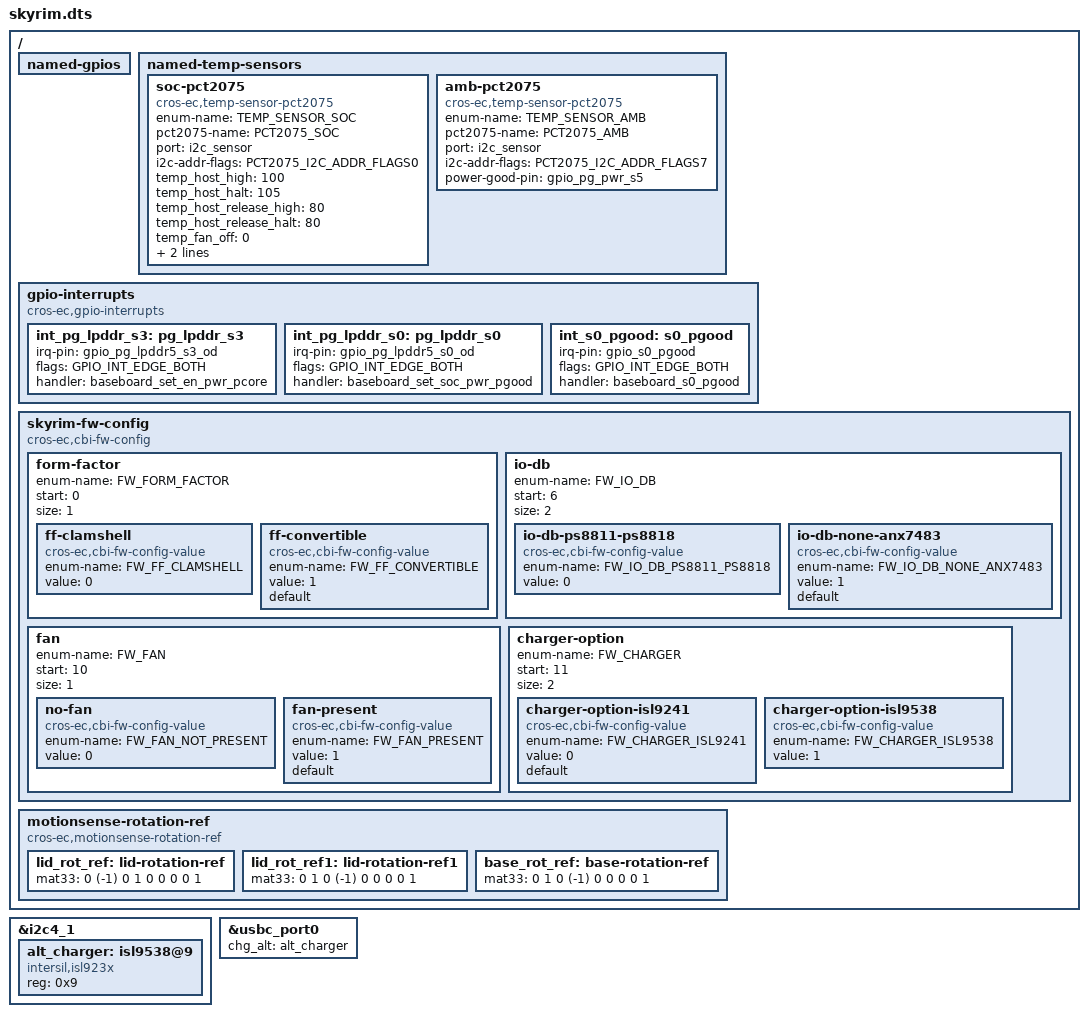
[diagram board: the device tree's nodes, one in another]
/* Copyright 2021 The Chromium OS Authors. All rights reserved.
 * Use of this source code is governed by a BSD-style license that can be
 * found in the LICENSE file.
 */

/ {
	named-gpios {
		/* Skyrim-specific GPIO customizations */
	};

	named-temp-sensors {
		soc-pct2075 {
			compatible = "cros-ec,temp-sensor-pct2075",
				     "cros-ec,temp-sensor";
			enum-name = "TEMP_SENSOR_SOC";
			pct2075-name = "PCT2075_SOC";
			port = <&i2c_sensor>;
			i2c-addr-flags = "PCT2075_I2C_ADDR_FLAGS0";
			temp_host_high = <100>;
			temp_host_halt = <105>;
			temp_host_release_high = <80>;
			temp_host_release_halt = <80>;
			temp_fan_off = <0>;
			temp_fan_max = <70>;
			power-good-pin = <&gpio_pg_pwr_s5>;
		};
		amb-pct2075 {
			compatible = "cros-ec,temp-sensor-pct2075",
				     "cros-ec,temp-sensor";
			enum-name = "TEMP_SENSOR_AMB";
			pct2075-name = "PCT2075_AMB";
			port = <&i2c_sensor>;
			i2c-addr-flags = "PCT2075_I2C_ADDR_FLAGS7";
			power-good-pin = <&gpio_pg_pwr_s5>;
		};
	};

	gpio-interrupts {
		compatible = "cros-ec,gpio-interrupts";

		int_pg_lpddr_s3: pg_lpddr_s3 {
			irq-pin = <&gpio_pg_lpddr5_s3_od>;
			flags = <GPIO_INT_EDGE_BOTH>;
			handler = "baseboard_set_en_pwr_pcore";
		};
		int_pg_lpddr_s0: pg_lpddr_s0 {
			irq-pin = <&gpio_pg_lpddr5_s0_od>;
			flags = <GPIO_INT_EDGE_BOTH>;
			handler = "baseboard_set_soc_pwr_pgood";
		};
		int_s0_pgood: s0_pgood {
			irq-pin = <&gpio_s0_pgood>;
			flags = <GPIO_INT_EDGE_BOTH>;
			handler = "baseboard_s0_pgood";
		};
	};

	/*
	 * Note this is expected to vary per-board, so we keep it in the board
	 * dts files.
	 */
	skyrim-fw-config {
		compatible = "cros-ec,cbi-fw-config";

		form-factor {
			enum-name = "FW_FORM_FACTOR";
			start = <0>;
			size = <1>;

			ff-clamshell {
				compatible = "cros-ec,cbi-fw-config-value";
				enum-name = "FW_FF_CLAMSHELL";
				value = <0>;
			};
			ff-convertible {
				compatible = "cros-ec,cbi-fw-config-value";
				enum-name = "FW_FF_CONVERTIBLE";
				value = <1>;
				default;
			};
		};
		io-db {
			enum-name = "FW_IO_DB";
			start = <6>;
			size = <2>;

			io-db-ps8811-ps8818 {
				compatible = "cros-ec,cbi-fw-config-value";
				enum-name = "FW_IO_DB_PS8811_PS8818";
				value = <0>;
			};
			io-db-none-anx7483 {
				compatible = "cros-ec,cbi-fw-config-value";
				enum-name = "FW_IO_DB_NONE_ANX7483";
				value = <1>;
				default;
			};
		};

		/*
		 * FW_CONFIG field to enable fan or not.
		 */
		fan {
			enum-name = "FW_FAN";
			start = <10>;
			size = <1>;

			no-fan {
				compatible = "cros-ec,cbi-fw-config-value";
				enum-name = "FW_FAN_NOT_PRESENT";
				value = <0>;
			};
			fan-present {
				compatible = "cros-ec,cbi-fw-config-value";
				enum-name = "FW_FAN_PRESENT";
				value = <1>;
				/*
				 * Set as default so that unprovisioned
				 * configs will run the fan regardless.
				 */
				default;
			};
		};

		charger-option {
			enum-name = "FW_CHARGER";
			start = <11>;
			size = <2>;

			charger-option-isl9241 {
				compatible = "cros-ec,cbi-fw-config-value";
				enum-name = "FW_CHARGER_ISL9241";
				value = <0>;
				default;
			};
			charger-option-isl9538 {
				compatible = "cros-ec,cbi-fw-config-value";
				enum-name = "FW_CHARGER_ISL9538";
				value = <1>;
			};
		};
	};

	/* Rotation matrices for motion sensors. */
	motionsense-rotation-ref {
		compatible = "cros-ec,motionsense-rotation-ref";
		lid_rot_ref: lid-rotation-ref {
			mat33 = <0 (-1) 0
				 1 0 0
				 0 0 1>;
		};

		lid_rot_ref1: lid-rotation-ref1 {
			mat33 = <0 1 0
				 (-1) 0 0
				 0 0 1>;
		};

		base_rot_ref: base-rotation-ref {
			mat33 = <0 1 0
				 (-1) 0 0
				 0 0 1>;
		};
	};
};

&i2c4_1 {
	alt_charger: isl9538@9 {
		compatible = "intersil,isl923x";
		status = "okay";
		reg = <0x9>;
	};
};

&usbc_port0 {
	chg_alt = <&alt_charger>;
};
